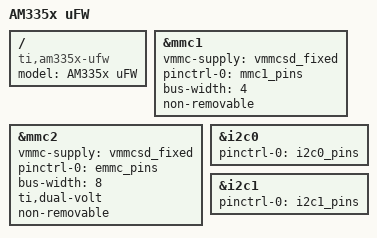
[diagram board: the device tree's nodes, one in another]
/*-
 * Copyright (c) 2016 Rubicon Communications, LLC (Netgate)
 * All rights reserved.
 *
 * Redistribution and use in source and binary forms, with or without
 * modification, are permitted provided that the following conditions
 * are met:
 * 1. Redistributions of source code must retain the above copyright
 *    notice, this list of conditions and the following disclaimer.
 * 2. Redistributions in binary form must reproduce the above copyright
 *    notice, this list of conditions and the following disclaimer in the
 *    documentation and/or other materials provided with the distribution.
 *
 * THIS SOFTWARE IS PROVIDED BY THE AUTHOR AND CONTRIBUTORS ``AS IS'' AND
 * ANY EXPRESS OR IMPLIED WARRANTIES, INCLUDING, BUT NOT LIMITED TO, THE
 * IMPLIED WARRANTIES OF MERCHANTABILITY AND FITNESS FOR A PARTICULAR PURPOSE
 * ARE DISCLAIMED.  IN NO EVENT SHALL THE AUTHOR OR CONTRIBUTORS BE LIABLE
 * FOR ANY DIRECT, INDIRECT, INCIDENTAL, SPECIAL, EXEMPLARY, OR CONSEQUENTIAL
 * DAMAGES (INCLUDING, BUT NOT LIMITED TO, PROCUREMENT OF SUBSTITUTE GOODS
 * OR SERVICES; LOSS OF USE, DATA, OR PROFITS; OR BUSINESS INTERRUPTION)
 * HOWEVER CAUSED AND ON ANY THEORY OF LIABILITY, WHETHER IN CONTRACT, STRICT
 * LIABILITY, OR TORT (INCLUDING NEGLIGENCE OR OTHERWISE) ARISING IN ANY WAY
 * OUT OF THE USE OF THIS SOFTWARE, EVEN IF ADVISED OF THE POSSIBILITY OF
 * SUCH DAMAGE.
 * 
 * $FreeBSD$
 */

/dts-v1/;

#include "am33xx.dtsi"
#include "ubmc.dtsi"

/ {
	model = "AM335x uFW";
	compatible = "ti,am335x-ufw", "ti,am335x-ubmc", "ti,am33xx";
};

&mmc1 {
	vmmc-supply = <&vmmcsd_fixed>;
	pinctrl-names = "default";
	pinctrl-0 = <&mmc1_pins>;
	bus-width = <4>;
	non-removable;
	status = "okay";
};

&mmc2 {
	vmmc-supply = <&vmmcsd_fixed>;
	pinctrl-names = "default";
	pinctrl-0 = <&emmc_pins>;
	bus-width = <8>;
	ti,dual-volt;
	non-removable;
	status = "okay";
};

&i2c0 {
	pinctrl-names = "default";
	pinctrl-0 = <&i2c0_pins>;

	status = "okay";
};

&i2c1 {
	pinctrl-names = "default";
	pinctrl-0 = <&i2c1_pins>;

	status = "okay";
};
